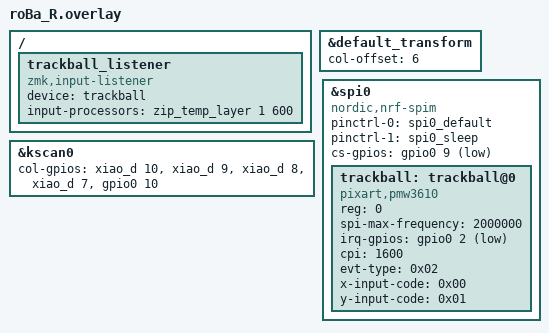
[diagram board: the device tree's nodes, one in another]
#include "roBa.dtsi"
#include <zephyr/dt-bindings/input/input-event-codes.h>
#include <input/processors.dtsi>
#include <dt-bindings/zmk/input_transform.h>

&default_transform {
    col-offset = <6>;
};

&kscan0 {
        col-gpios
            = <&xiao_d 10 GPIO_ACTIVE_HIGH>
            , <&xiao_d 9 GPIO_ACTIVE_HIGH> 
            , <&xiao_d 8 GPIO_ACTIVE_HIGH> 
            , <&xiao_d 7 GPIO_ACTIVE_HIGH> 
            , <&gpio0 10 GPIO_ACTIVE_HIGH>
            ;
};

// Use existing SPI pinctrl from roBa.dtsi
&spi0 {
    status = "okay";
    compatible = "nordic,nrf-spim";
    pinctrl-0 = <&spi0_default>;
    pinctrl-1 = <&spi0_sleep>;
    pinctrl-names = "default", "sleep";
    cs-gpios = <&gpio0 9 GPIO_ACTIVE_LOW>;

    trackball: trackball@0 {
        status = "okay";
        compatible = "pixart,pmw3610";
        reg = <0>;
        spi-max-frequency = <2000000>;
        irq-gpios = <&gpio0 2 (GPIO_ACTIVE_LOW | GPIO_PULL_UP)>;
        
        // PMW3610 specific configuration for better responsiveness
        cpi = <1600>;
        evt-type = <0x02>;
        x-input-code = <0x00>;
        y-input-code = <0x01>;
    };
};

/ {
    // ZMK official auto mouse layer implementation using zip_temp_layer
    trackball_listener: trackball_listener {
        compatible = "zmk,input-listener";
        device = <&trackball>;
        status = "okay";
        input-processors = <&zip_temp_layer 1 600>;  // Layer 1, 600ms timeout for responsive switching
    };
};


